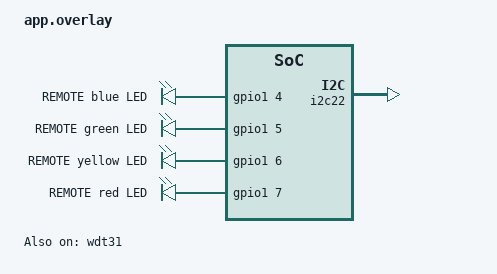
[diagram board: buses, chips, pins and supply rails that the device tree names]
/* ASSUMED active-high, same as BLUE; NOT verified (MAX-43); verify with a current-limited test before trusting. */
#include <zephyr/dt-bindings/gpio/gpio.h>

/*
 * EXTERNAL antenna (owner decision 2026-11-03: an antenna is connected to every XIAO nRF54L15): P2.05 HIGH, RF switch power P2.03 HIGH.
 * The on-board ceramic antenna is P2.05 LOW (the board default). With this overlay a board WITHOUT an antenna on the u.FL connector
 * has no usable radio: connect the antenna before flashing, or change P2.05 back to GPIO_ACTIVE_LOW.
 */
&rfsw_ctl {
    enable-gpios = <&gpio2 5 GPIO_ACTIVE_HIGH>;
    regulator-boot-on;
};

&rfsw_pwr {
    enable-gpios = <&gpio2 3 GPIO_ACTIVE_HIGH>;
    regulator-boot-on;
};

/
{
    aliases {
        blue-led = &blue_led;
        logger-green = &logger_green;
        logger-yellow = &logger_yellow;
        logger-red = &logger_red;
    };

    leds {
        compatible = "gpio-leds";
        blue_led: led_1 {
            gpios = <&gpio1 4 GPIO_ACTIVE_HIGH>;
            label = "REMOTE blue LED";
        };
        logger_green: led_2 {
            gpios = <&gpio1 5 GPIO_ACTIVE_HIGH>;
            label = "REMOTE green LED";
        };
        logger_yellow: led_3 {
            gpios = <&gpio1 6 GPIO_ACTIVE_HIGH>;
            label = "REMOTE yellow LED";
        };
        logger_red: led_4 {
            gpios = <&gpio1 7 GPIO_ACTIVE_HIGH>;
            label = "REMOTE red LED";
        };
    };
};

/*
 * Project-level corrections for the plain Seeed Studio XIAO nRF54L15.
 *
 * The pinned Seeed board definition currently describes a Sense-style
 * LSM6DS3TR-C on i2c30 and exposes it as imu0. The diploma hardware uses the
 * plain XIAO and an external GY-BMI160 on the private D11/D12 bus instead.
 * Keep i2c30 itself enabled; only disable the nonexistent onboard IMU node.
 *
 * The same board definition maps D4/D5 to i2c22 as TWIM by default. This
 * project uses that peripheral as the upstream I2C target, so only i2c22 is
 * switched to TWIS. The private i2c30 sensor bus remains TWIM/controller.
 *
 * i2c22 has no internal bias-pull-up: ESP32-S3 already owns the pull-up on
 * this shared bus (components/sensor_bus/sensor_bus.c, GPIO9/GPIO10). A
 * second pull-up here is unnecessary on a normal I2C bus and is a candidate
 * contributor to the MAIN-enclosure XIAO boot-interaction under
 * investigation (Linear MAX-108/MAX-116): when this node is unpowered while
 * ESP32 still holds the shared lines high, an enabled pull-up structure is
 * an avoidable additional path back into this node's VDD rail.
 */

/ {
    aliases {
        /delete-property/ imu0;
    };

    /*
     * Console on the XIAO header instead of the on-board USB bridge (uart20),
     * so a USB-UART adapter can log a node that is powered from the enclosure
     * without connecting its USB-C: D6 = P2.08 = TX, D7 = P2.07 = RX, 115200
     * 8N1, 3.3 V logic. Join the adapter GND to the node GND.
     */
    chosen {
        zephyr,console = &uart21;
    };
};

&lsm6ds3tr_c {
    status = "disabled";
};

&i2c22_default {
    group1 {
        psels = <NRF_PSEL(TWIS_SDA, 1, 10)>,
                <NRF_PSEL(TWIS_SCL, 1, 11)>;
    };
};

&i2c22_sleep {
    group1 {
        psels = <NRF_PSEL(TWIS_SDA, 1, 10)>,
                <NRF_PSEL(TWIS_SCL, 1, 11)>;
    };
};

/* MAX-244: application watchdog (alias watchdog0 on this board). */
&wdt31 {
    status = "okay";
};

&i2c22 {
    compatible = "nordic,nrf-twis";
    pinctrl-0 = <&i2c22_default>;
    pinctrl-1 = <&i2c22_sleep>;
    pinctrl-names = "default", "sleep";
    status = "okay";
};
